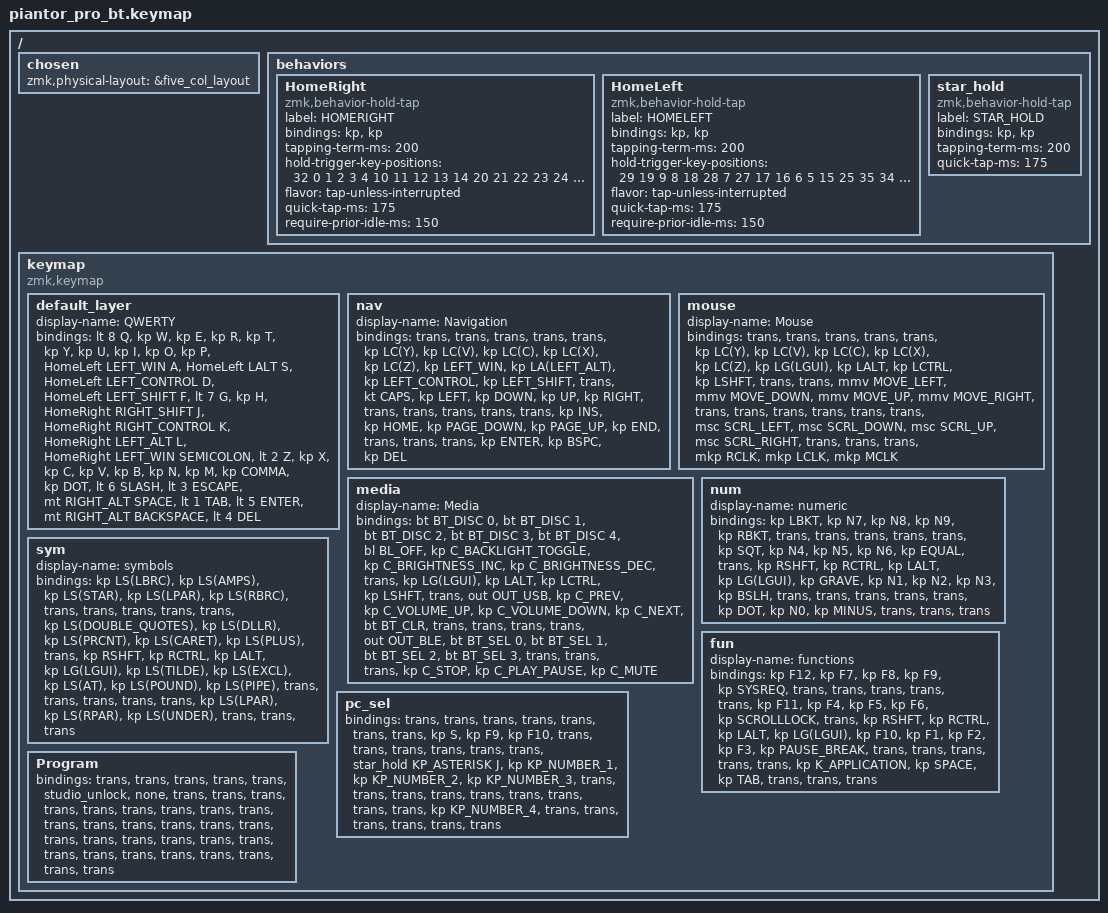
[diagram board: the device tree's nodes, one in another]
/*
 * Copyright (c) 2020 The ZMK Contributors
 *
 * SPDX-License-Identifier: MIT
 */

#include <behaviors.dtsi>
#include <dt-bindings/zmk/backlight.h>
#include <dt-bindings/zmk/bt.h>
#include <dt-bindings/zmk/keys.h>
#include <dt-bindings/zmk/outputs.h>
#include <dt-bindings/zmk/pointing.h>

/ {
    chosen { zmk,physical-layout = &five_col_layout; };
};

/ {
    behaviors {
        HomeRight: HomeRight {
            compatible = "zmk,behavior-hold-tap";
            label = "HOMERIGHT";
            bindings = <&kp>, <&kp>;

            #binding-cells = <2>;
            tapping-term-ms = <200>;
            hold-trigger-key-positions = <32 0 1 2 3 4 10 11 12 13 14 20 21 22 23 24 30 31>;
            flavor = "tap-unless-interrupted";
            quick-tap-ms = <175>;
            require-prior-idle-ms = <150>;
        };

        HomeLeft: HomeLeft {
            compatible = "zmk,behavior-hold-tap";
            label = "HOMELEFT";
            bindings = <&kp>, <&kp>;

            #binding-cells = <2>;
            tapping-term-ms = <200>;
            hold-trigger-key-positions = <29 19 9 8 18 28 7 27 17 16 6 5 15 25 35 34 33 26>;
            flavor = "tap-unless-interrupted";
            quick-tap-ms = <175>;
            require-prior-idle-ms = <150>;
        };

        star_hold: star_hold {
            compatible = "zmk,behavior-hold-tap";
            label = "STAR_HOLD";
            bindings = <&kp>, <&kp>;

            #binding-cells = <2>;
            tapping-term-ms = <200>;
            quick-tap-ms = <175>;
        };
    };

    keymap {
        compatible = "zmk,keymap";

        default_layer {
            display-name = "QWERTY";

            // --------------------------------------------------------------
            // |  Q  |  W  |  E  |  R  |  T  |  Y  |  U   |  I  |  O  |  P  |
            // |  A  |  S  |  D  |  F  |  G  |  H  |  J   |  K  |  L  |  ;  |
            // |  Z  |  X  |  C  |  V  |  B  |  N  |  M   |  ,  |  .  |  /  |
            //                    | GUI | LWR | SPC | ENT | RSE  | ALT |

            bindings = <
  &lt 8 Q  &kp W  &kp E  &kp R  &kp T  &kp Y  &kp U  &kp I  &kp O  &kp P      &HomeLeft LEFT_WIN A  &HomeLeft LALT S  &HomeLeft LEFT_CONTROL D  &HomeLeft LEFT_SHIFT F  &lt 7 G  &kp H  &HomeRight RIGHT_SHIFT J  &HomeRight RIGHT_CONTROL K  &HomeRight LEFT_ALT L  &HomeRight LEFT_WIN SEMICOLON      &lt 2 Z  &kp X  &kp C  &kp V  &kp B  &kp N  &kp M  &kp COMMA  &kp DOT  &lt 6 SLASH    &lt 3 ESCAPE  &mt RIGHT_ALT SPACE  &lt 1 TAB  &lt 5 ENTER  &mt RIGHT_ALT BACKSPACE  &lt 4 DEL
            >;
        };

        nav {
            display-name = "Navigation";
            bindings = <
  &trans  &trans  &trans  &trans  &trans  &kp LC(Y)  &kp LC(V)  &kp LC(C)  &kp LC(X)  &kp LC(Z)      &kp LEFT_WIN  &kp LA(LEFT_ALT)  &kp LEFT_CONTROL  &kp LEFT_SHIFT  &trans  &kt CAPS  &kp LEFT  &kp DOWN  &kp UP  &kp RIGHT      &trans  &trans  &trans  &trans  &trans  &kp INS  &kp HOME  &kp PAGE_DOWN  &kp PAGE_UP  &kp END    &trans  &trans  &trans  &kp ENTER  &kp BSPC  &kp DEL
            >;
        };

        mouse {
            display-name = "Mouse";
            bindings = <
  &trans  &trans  &trans  &trans  &trans  &kp LC(Y)  &kp LC(V)  &kp LC(C)  &kp LC(X)  &kp LC(Z)      &kp LG(LGUI)  &kp LALT  &kp LCTRL  &kp LSHFT  &trans  &trans  &mmv MOVE_LEFT  &mmv MOVE_DOWN  &mmv MOVE_UP  &mmv MOVE_RIGHT      &trans  &trans  &trans  &trans  &trans  &trans  &msc SCRL_LEFT  &msc SCRL_DOWN  &msc SCRL_UP  &msc SCRL_RIGHT    &trans  &trans  &trans  &mkp RCLK  &mkp LCLK  &mkp MCLK
            >;
        };

        media {
            display-name = "Media";
            bindings = <
  &bt BT_DISC 0  &bt BT_DISC 1  &bt BT_DISC 2  &bt BT_DISC 3  &bt BT_DISC 4  &bl BL_OFF  &kp C_BACKLIGHT_TOGGLE  &kp C_BRIGHTNESS_INC  &kp C_BRIGHTNESS_DEC  &trans      &kp LG(LGUI)  &kp LALT  &kp LCTRL  &kp LSHFT  &trans  &out OUT_USB  &kp C_PREV  &kp C_VOLUME_UP  &kp C_VOLUME_DOWN  &kp C_NEXT      &bt BT_CLR  &trans  &trans  &trans  &trans  &out OUT_BLE  &bt BT_SEL 0  &bt BT_SEL 1  &bt BT_SEL 2  &bt BT_SEL 3    &trans  &trans  &trans  &kp C_STOP  &kp C_PLAY_PAUSE  &kp C_MUTE
            >;
        };

        num {
            display-name = "numeric";
            bindings = <
  &kp LBKT  &kp N7  &kp N8  &kp N9  &kp RBKT  &trans  &trans  &trans  &trans  &trans      &kp SQT  &kp N4  &kp N5  &kp N6  &kp EQUAL  &trans  &kp RSHFT  &kp RCTRL  &kp LALT  &kp LG(LGUI)      &kp GRAVE  &kp N1  &kp N2  &kp N3  &kp BSLH  &trans  &trans  &trans  &trans  &trans    &kp DOT  &kp N0  &kp MINUS  &trans  &trans  &trans
            >;
        };

        sym {
            display-name = "symbols";
            bindings = <
  &kp LS(LBRC)  &kp LS(AMPS)  &kp LS(STAR)  &kp LS(LPAR)  &kp LS(RBRC)  &trans  &trans  &trans  &trans  &trans      &kp LS(DOUBLE_QUOTES)  &kp LS(DLLR)  &kp LS(PRCNT)  &kp LS(CARET)  &kp LS(PLUS)  &trans  &kp RSHFT  &kp RCTRL  &kp LALT  &kp LG(LGUI)      &kp LS(TILDE)  &kp LS(EXCL)  &kp LS(AT)  &kp LS(POUND)  &kp LS(PIPE)  &trans  &trans  &trans  &trans  &trans    &kp LS(LPAR)  &kp LS(RPAR)  &kp LS(UNDER)  &trans  &trans  &trans
            >;
        };

        fun {
            display-name = "functions";
            bindings = <
  &kp F12  &kp F7  &kp F8  &kp F9  &kp SYSREQ  &trans  &trans  &trans  &trans  &trans      &kp F11  &kp F4  &kp F5  &kp F6  &kp SCROLLLOCK  &trans  &kp RSHFT  &kp RCTRL  &kp LALT  &kp LG(LGUI)      &kp F10  &kp F1  &kp F2  &kp F3  &kp PAUSE_BREAK  &trans  &trans  &trans  &trans  &trans    &kp K_APPLICATION  &kp SPACE  &kp TAB  &trans  &trans  &trans
            >;
        };

        pc_sel {
            bindings = <
  &trans  &trans  &trans  &trans  &trans  &trans  &trans  &kp S  &kp F9  &kp F10      &trans  &trans  &trans  &trans  &trans  &trans  &star_hold KP_ASTERISK J  &kp KP_NUMBER_1  &kp KP_NUMBER_2  &kp KP_NUMBER_3      &trans  &trans  &trans  &trans  &trans  &trans  &trans  &trans  &trans  &kp KP_NUMBER_4    &trans  &trans  &trans  &trans  &trans  &trans
            >;
        };

        Program {
            bindings = <
  &trans  &trans  &trans  &trans  &trans  &studio_unlock  &none  &trans  &trans  &trans      &trans  &trans  &trans  &trans  &trans  &trans  &trans  &trans  &trans  &trans      &trans  &trans  &trans  &trans  &trans  &trans  &trans  &trans  &trans  &trans    &trans  &trans  &trans  &trans  &trans  &trans
            >;
        };
    };
};
